# PCIe_SS1_TI_CONF register map
Vendor: Texas Instruments
Peripheral module from a debugger description file (folder am571x).
Registers are 32-bit, access per field, reset 0x0 unless marked. A register's access mark holds for its fields unless they carry their own. Offsets are as the file gives them; lines under a group give offsets from that group; [hi:lo] are bit positions; {n}, {i} and the like mark numbered series; 'fields as' and 'values as' point back to an identical list; <NAME> marks a mode.

## PCIe_SS1_TI_CONF
0x00 PCIECTRL_TI_CONF_REVISION ro reset not defined — IP Revision Identifier
  [31:0] REVISION — IP Revision
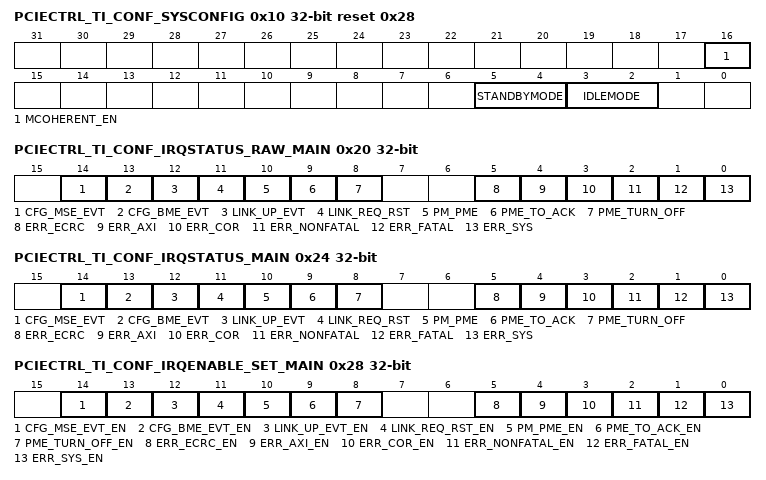
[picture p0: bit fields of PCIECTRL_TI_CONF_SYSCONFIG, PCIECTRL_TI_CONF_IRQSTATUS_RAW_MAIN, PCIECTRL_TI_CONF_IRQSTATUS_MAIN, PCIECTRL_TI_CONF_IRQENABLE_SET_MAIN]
0x10 PCIECTRL_TI_CONF_SYSCONFIG reset 0x28 — Controls various parameters of the master and slave interfaces.
  [16] MCOHERENT_EN rw — Allows the no-snoop (NS) attribute of inbound PCIe TLPs to be passed to SoC system bus (AXI) master as a 'coherent' inband flag.
    0=DIS (DIS AXI not coherent); 1=EN (EN AXI coherent = not(PCIE 'NS') that is, cache-coherence is preserved)
  [5:4] STANDBYMODE rw — PM mode of local initiator (master); Initiator may generate read/write transaction as long as it is out of STANDBY state. 0x0: Force-standby mode = Initiator is unconditionally placed in standby state. 0x1: No-standby mode = initiator is unconditionally placed out of standby state. 0x2: Smart-standby mode = initiator's standby state depends on internal conditions, that is, the module's functional requirements. Asynchronous wakeup events cannot be generated. 0x3: Smart-Standby, wakeup-capable mode = initiator's standby state depends on internal conditions, ie the module's functional requirements. Asynchronous wakeup events can be generated.
  [3:2] IDLEMODE rw — PM mode of local target (slave); Target shall be capable of handling read/write transaction as long as it is out of IDLE state. 0x0: Force-idle mode = local target's idle state follows (acknowledges) the system's idle requests unconditionally, regardless of the IP module's internal requirements. 0x1: No-idle mode = local target never enters idle state. 0x2: Smart-idle mode = local target's idle state eventually follows (acknowledges) the system's idle requests, depending on the IP module's internal requirements. Module shall not generate (IRQ- or DMA-request-related) wakeup events. 0x3: Smart-idle wakeup-capable mode: local target's idle state eventually follows (acknowledges) the system's idle requests, depending on the IP module's internal requirements. IP module may generate (IRQ- or DMA-request-related) wakeup events when in idle state.
0x18 PCIECTRL_TI_CONF_IRQ_EOI — Software End-Of-Interrupt: Allows the generation of further pulses on the interrupt line, if an new interrupt event is pending, when using the pulsed output. Unused when using the level interrupt line (depending on module integration).
  [3:0] LINE_NUMBER rw — Write the IRQ line number to apply software EOI to it. Write 0x0: software EOI on main interrupt line Read 0x0: Read always returns zeros Write 0x1: software EOI on message-signalled (MSI) interrupt line
0x20 PCIECTRL_TI_CONF_IRQSTATUS_RAW_MAIN access not given — Raw status of 'main' interrupt requests; Set even if event is not enabled. Write 1 to set the (raw) status, mostly for debug (regular status also gets set).
  [14] CFG_MSE_EVT — CFG 'Memory Space Enable' change IRQ status Write 0: No action Read 0: No event pending Write 1: Trigger IRQ event by software Read 1: IRQ event pending (access RW W1toSet)
  [13] CFG_BME_EVT — CFG 'Bus Master Enable' change IRQ status Write 0: No action Read 0: No event pending Write 1: Trigger IRQ event by software Read 1: IRQ event pending (access RW W1toSet)
  [12] LINK_UP_EVT — Link-up state change IRQ status Write 0: No action Read 0: No event pending Write 1: Trigger IRQ event by software Read 1: IRQ event pending (access RW W1toSet)
  [11] LINK_REQ_RST — Link Request Reset IRQ status Write 0: No action Read 0: No event pending Write 1: Trigger IRQ event by software Read 1: IRQ event pending (access RW W1toSet)
  [10] PM_PME — PM Power Management Event message received IRQ status Write 0: No action Read 0: No event pending Write 1: Trigger IRQ event by software Read 1: IRQ event pending (access RW W1toSet)
  [9] PME_TO_ACK — Power Management Event Turn-Off Ack message received IRQ status Write 0: No action Read 0: No event pending Write 1: Trigger IRQ event by software Read 1: IRQ event pending (access RW W1toSet)
  [8] PME_TURN_OFF — Power Management Event Turn-Off message received IRQ status Write 0: No action Read 0: No event pending Write 1: Trigger IRQ event by software Read 1: IRQ event pending (access RW W1toSet)
  [5] ERR_ECRC — ECRC Error IRQ status Write 0: No action Read 0: No event pending Write 1: Trigger IRQ event by software Read 1: IRQ event pending (access RW W1toSet)
  [4] ERR_AXI — AXI tag lookup fatal Error IRQ status Write 0: No action Read 0: No event pending Write 1: Trigger IRQ event by software Read 1: IRQ event pending (access RW W1toSet)
  [3] ERR_COR — Correctable Error message received IRQ status Write 0: No action Read 0: No event pending Write 1: Trigger IRQ event by software Read 1: IRQ event pending (access RW W1toSet)
  [2] ERR_NONFATAL — Non-Fatal Error message received IRQ status Write 0: No action Read 0: No event pending Write 1: Trigger IRQ event by software Read 1: IRQ event pending (access RW W1toSet)
  [1] ERR_FATAL — Fatal Error message received IRQ status Write 0: No action Read 0: No event pending Write 1: Trigger IRQ event by software Read 1: IRQ event pending (access RW W1toSet)
  [0] ERR_SYS — System Error IRQ status Write 0: No action Read 0: No event pending Write 1: Trigger IRQ event by software Read 1: IRQ event pending (access RW W1toSet)
0x24 PCIECTRL_TI_CONF_IRQSTATUS_MAIN access not given — Regular status of 'main' interrupt requests; Set only when enabled. Write 1 to clear after interrupt has been serviced (raw status also gets cleared).
  [14] CFG_MSE_EVT — CFG 'Memory Space Enable' change IRQ status Write 0: No action Read 0: No event pending Write 1: Clear pending event, if any Read 1: IRQ event pending (access RW W1toClr)
  [13] CFG_BME_EVT — CFG 'Bus Master Enable' change IRQ status Write 0: No action Read 0: No event pending Write 1: Clear pending event, if any Read 1: IRQ event pending (access RW W1toClr)
  [12] LINK_UP_EVT — Link-up state change IRQ status Write 0: No action Read 0: No event pending Write 1: Clear pending event, if any Read 1: IRQ event pending (access RW W1toClr)
  [11] LINK_REQ_RST — Link Request Reset IRQ status Write 0: No action Read 0: No event pending Write 1: Clear pending event, if any Read 1: IRQ event pending (access RW W1toClr)
  [10] PM_PME — PM Power Management Event message received IRQ status Write 0: No action Read 0: No event pending Write 1: Clear pending event, if any Read 1: IRQ event pending (access RW W1toClr)
  [9] PME_TO_ACK — Power Management Event Turn-Off Ack message received IRQ status Write 0: No action Read 0: No event pending Write 1: Clear pending event, if any Read 1: IRQ event pending (access RW W1toClr)
  [8] PME_TURN_OFF — Power Management Event Turn-Off message received IRQ status Write 0: No action Read 0: No event pending Write 1: Clear pending event, if any Read 1: IRQ event pending (access RW W1toClr)
  [5] ERR_ECRC — ECRC Error IRQ status Write 0: No action Read 0: No event pending Write 1: Clear pending event, if any Read 1: IRQ event pending (access RW W1toClr)
  [4] ERR_AXI — AXI tag lookup fatal Error IRQ status Write 0: No action Read 0: No event pending Write 1: Clear pending event, if any Read 1: IRQ event pending (access RW W1toClr)
  [3] ERR_COR — Correctable Error message received IRQ status Write 0: No action Read 0: No event pending Write 1: Clear pending event, if any Read 1: IRQ event pending (access RW W1toClr)
  [2] ERR_NONFATAL — Non-Fatal Error message received IRQ status Write 0: No action Read 0: No event pending Write 1: Clear pending event, if any Read 1: IRQ event pending (access RW W1toClr)
  [1] ERR_FATAL — Fatal Error message received IRQ status Write 0: No action Read 0: No event pending Write 1: Clear pending event, if any Read 1: IRQ event pending (access RW W1toClr)
  [0] ERR_SYS — System Error IRQ status Write 0: No action Read 0: No event pending Write 1: Clear pending event, if any Read 1: IRQ event pending (access RW W1toClr)
0x28 PCIECTRL_TI_CONF_IRQENABLE_SET_MAIN access not given — Enable of 'main' interrupt requests; Write 1 to set (ie to enable interrupt). Readout is the same as corresponding _CLR register.
  [14] CFG_MSE_EVT_EN — CFG 'Memory Space Enable' change IRQ enable Write 0: No action Read 0: IRQ event is disabled Write 1: Set IRQ enable (that is, enable event) Read 1: IRQ event is enabled (access RW W1toSet)
  [13] CFG_BME_EVT_EN — CFG 'Bus Master Enable' change IRQ enable Write 0: No action Read 0: IRQ event is disabled Write 1: Set IRQ enable (that is, enable event) Read 1: IRQ event is enabled (access RW W1toSet)
  [12] LINK_UP_EVT_EN — Link-up state change IRQ enable Write 0: No action Read 0: IRQ event is disabled Write 1: Set IRQ enable (that is, enable event) Read 1: IRQ event is enabled (access RW W1toSet)
  [11] LINK_REQ_RST_EN — Link Request Reset IRQ enable Write 0: No action Read 0: IRQ event is disabled Write 1: Set IRQ enable (that is, enable event) Read 1: IRQ event is enabled (access RW W1toSet)
  [10] PM_PME_EN — PM Power Management Event message received IRQ enable Write 0: No action Read 0: IRQ event is disabled Write 1: Set IRQ enable (that is, enable event) Read 1: IRQ event is enabled (access RW W1toSet)
  [9] PME_TO_ACK_EN — Power Management Event Turn-Off Ack message received IRQ enable Write 0: No action Read 0: IRQ event is disabled Write 1: Set IRQ enable (that is, enable event) Read 1: IRQ event is enabled (access RW W1toSet)
  [8] PME_TURN_OFF_EN — Power Management Event Turn-Off message received IRQ enable Write 0: No action Read 0: IRQ event is disabled Write 1: Set IRQ enable (that is, enable event) Read 1: IRQ event is enabled (access RW W1toSet)
  [5] ERR_ECRC_EN — ECRC Error IRQ enable Write 0: No action Read 0: IRQ event is disabled Write 1: Set IRQ enable (that is, enable event) Read 1: IRQ event is enabled (access RW W1toSet)
  [4] ERR_AXI_EN — AXI tag lookup fatal Error IRQ enable Write 0: No action Read 0: IRQ event is disabled Write 1: Set IRQ enable (that is, enable event) Read 1: IRQ event is enabled (access RW W1toSet)
  [3] ERR_COR_EN — Correctable Error message received IRQ enable Write 0: No action Read 0: IRQ event is disabled Write 1: Set IRQ enable (that is, enable event) Read 1: IRQ event is enabled (access RW W1toSet)
  [2] ERR_NONFATAL_EN — Non-Fatal Error message received IRQ enable Write 0: No action Read 0: IRQ event is disabled Write 1: Set IRQ enable (that is, enable event) Read 1: IRQ event is enabled (access RW W1toSet)
  [1] ERR_FATAL_EN — Fatal Error message received IRQ enable Write 0: No action Read 0: IRQ event is disabled Write 1: Set IRQ enable (that is, enable event) Read 1: IRQ event is enabled (access RW W1toSet)
  [0] ERR_SYS_EN — System Error IRQ enable Write 0: No action Read 0: IRQ event is disabled Write 1: Set IRQ enable (that is, enable event) Read 1: IRQ event is enabled (access RW W1toSet)
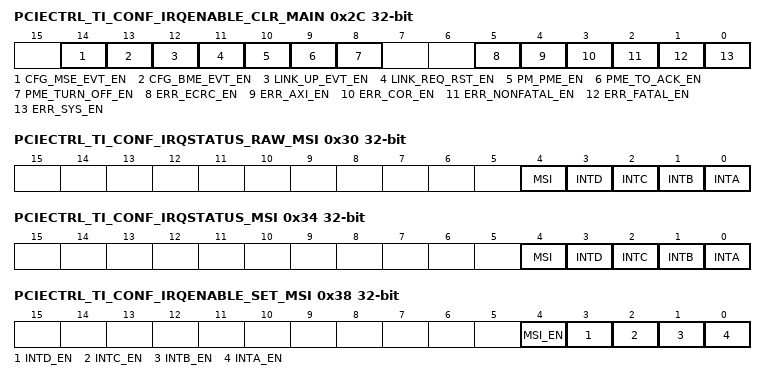
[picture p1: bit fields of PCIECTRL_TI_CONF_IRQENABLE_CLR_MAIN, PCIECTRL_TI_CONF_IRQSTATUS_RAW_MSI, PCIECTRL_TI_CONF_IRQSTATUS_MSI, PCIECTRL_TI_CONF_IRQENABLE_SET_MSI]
0x2C PCIECTRL_TI_CONF_IRQENABLE_CLR_MAIN access not given — Enable of 'main' interrupt requests; Write 1 to clear (ie to disable interrupt). Readout is the same as corresponding _SET register.
  [14] CFG_MSE_EVT_EN — CFG 'Memory Space Enable' change IRQ enable Write 0: No action Read 0: IRQ event is disabled Write 1: Clear IRQ enable (that is, disable event) Read 1: IRQ event is enabled (access RW Wr1toClr)
  [13] CFG_BME_EVT_EN — CFG 'Bus Master Enable' change IRQ enable Write 0: No action Read 0: IRQ event is disabled Write 1: Clear IRQ enable (that is, disable event) Read 1: IRQ event is enabled (access RW Wr1toClr)
  [12] LINK_UP_EVT_EN — Link-up state change IRQ enable Write 0: No action Read 0: IRQ event is disabled Write 1: Clear IRQ enable (that is, disable event) Read 1: IRQ event is enabled (access RW Wr1toClr)
  [11] LINK_REQ_RST_EN — Link Request Reset IRQ enable Write 0: No action Read 0: IRQ event is disabled Write 1: Clear IRQ enable (that is, disable event) Read 1: IRQ event is enabled (access RW Wr1toClr)
  [10] PM_PME_EN — PM Power Management Event message received IRQ enable Write 0: No action Read 0: IRQ event is disabled Write 1: Clear IRQ enable (that is, disable event) Read 1: IRQ event is enabled (access RW Wr1toClr)
  [9] PME_TO_ACK_EN — Power Management Event Turn-Off Ack message received IRQ enable Write 0: No action Read 0: IRQ event is disabled Write 1: Clear IRQ enable (that is, disable event) Read 1: IRQ event is enabled (access RW Wr1toClr)
  [8] PME_TURN_OFF_EN — Power Management Event Turn-Off message received IRQ enable Write 0: No action Read 0: IRQ event is disabled Write 1: Clear IRQ enable (that is, disable event) Read 1: IRQ event is enabled (access RW Wr1toClr)
  [5] ERR_ECRC_EN — ECRC Error IRQ enable Write 0: No action Read 0: IRQ event is disabled Write 1: Clear IRQ enable (that is, disable event) Read 1: IRQ event is enabled (access RW Wr1toClr)
  [4] ERR_AXI_EN — AXI tag lookup fatal Error IRQ enable Write 0: No action Read 0: IRQ event is disabled Write 1: Clear IRQ enable (that is, disable event) Read 1: IRQ event is enabled (access RW Wr1toClr)
  [3] ERR_COR_EN — Correctable Error message received IRQ enable Write 0: No action Read 0: IRQ event is disabled Write 1: Clear IRQ enable (that is, disable event) Read 1: IRQ event is enabled (access RW Wr1toClr)
  [2] ERR_NONFATAL_EN — Non-Fatal Error message received IRQ enable Write 0: No action Read 0: IRQ event is disabled Write 1: Clear IRQ enable (that is, disable event) Read 1: IRQ event is enabled (access RW Wr1toClr)
  [1] ERR_FATAL_EN — Fatal Error message received IRQ enable Write 0: No action Read 0: IRQ event is disabled Write 1: Clear IRQ enable (that is, disable event) Read 1: IRQ event is enabled (access RW Wr1toClr)
  [0] ERR_SYS_EN — System Error IRQ enable Write 0: No action Read 0: IRQ event is disabled Write 1: Clear IRQ enable (that is, disable event) Read 1: IRQ event is enabled (access RW Wr1toClr)
0x30 PCIECTRL_TI_CONF_IRQSTATUS_RAW_MSI access not given — Raw status of legacy and MSI interrupt requests; Set even if event is not enabled. Write 1 to set the (raw) status, mostly for debug (regular status also gets set).
  [4] MSI — Message Signaled Interrupt IRQ status Write 0: No action Read 0: No event pending Write 1: Trigger IRQ event by software Read 1: IRQ event pending (access RW W1toSet)
  [3] INTD — INTD IRQ status (Legacy PCIe message interrupt D); RC mode only. Write 0: No action Read 0: No event pending Write 1: Trigger IRQ event by software Read 1: IRQ event pending (access RW W1toSet)
  [2] INTC — INTC IRQ status (Legacy PCIe message interrupt C); RC mode only. Write 0: No action Read 0: No event pending Write 1: Trigger IRQ event by software Read 1: IRQ event pending (access RW W1toSet)
  [1] INTB — INTB IRQ status (Legacy PCIe message interrupt B); RC mode only. Write 0: No action Read 0: No event pending Write 1: Trigger IRQ event by software Read 1: IRQ event pending (access RW W1toSet)
  [0] INTA — INTA IRQ status (Legacy PCIe message interrupt A); RC mode only. Write 0: No action Read 0: No event pending Write 1: Trigger IRQ event by software Read 1: IRQ event pending (access RW W1toSet)
0x34 PCIECTRL_TI_CONF_IRQSTATUS_MSI access not given — Regular status of legacy and MSI interrupt requests; Set only when enabled. Write 1 to clear after interrupt has been serviced (raw status also gets cleared). HW-generated events are self-clearing.
  [4] MSI — Message Signaled Interrupt IRQ status. Cleared by clearing all vectors in the MSI controller (PL) registers Write 0: No action Read 0: No event pending Write 1: Clear pending event, if any. Read 1: IRQ event pending (access RW W1toClr)
  [3] INTD — INTD IRQ status (Legacy PCIe message interrupt D); RC mode only. Typically set AND cleared by the remote EP, without local software intervention. Write 0: No action Read 0: No event pending Write 1: Clear pending event, if any. Read 1: IRQ event pending (access RW W1toClr)
  [2] INTC — INTC IRQ status (Legacy PCIe message interrupt C); RC mode only. Typically set AND cleared by the remote EP, without local software intervention. Write 0: No action Read 0: No event pending Write 1: Clear pending event, if any. Read 1: IRQ event pending (access RW W1toClr)
  [1] INTB — INTB IRQ status (Legacy PCIe message interrupt B); RC mode only. Typically set AND cleared by the remote EP, without local software intervention. Write 0: No action Read 0: No event pending Write 1: Clear pending event, if any. Read 1: IRQ event pending (access RW W1toClr)
  [0] INTA — INTA IRQ status (Legacy PCIe message interrupt A); RC mode only. Typically set AND cleared by the remote EP, without local software intervention. Write 0: No action Read 0: No event pending Write 1: Clear pending event, if any. Read 1: IRQ event pending (access RW W1toClr)
0x38 PCIECTRL_TI_CONF_IRQENABLE_SET_MSI access not given — Enable of legacy and MSI interrupt requests; Write 1 to set (ie to enable interrupt). Readout is the same as corresponding _CLR register.
  [4] MSI_EN — Message Signaled Interrupt IRQ enable Write 0: No action Read 0: IRQ event is disabled Write 1: Set IRQ enable (that is, enable event) Read 1: IRQ event is enabled (access RW W1toSet)
  [3] INTD_EN — INTD IRQ enable Write 0: No action Read 0: IRQ event is disabled Write 1: Set IRQ enable (that is, enable event) Read 1: IRQ event is enabled (access RW W1toSet)
  [2] INTC_EN — INTC IRQ enable Write 0: No action Read 0: IRQ event is disabled Write 1: Set IRQ enable (that is, enable event) Read 1: IRQ event is enabled (access RW W1toSet)
  [1] INTB_EN — INTB IRQ enable Write 0: No action Read 0: IRQ event is disabled Write 1: Set IRQ enable (that is, enable event) Read 1: IRQ event is enabled (access RW W1toSet)
  [0] INTA_EN — INTA IRQ enable Write 0: No action Read 0: IRQ event is disabled Write 1: Set IRQ enable (that is, enable event) Read 1: IRQ event is enabled (access RW W1toSet)
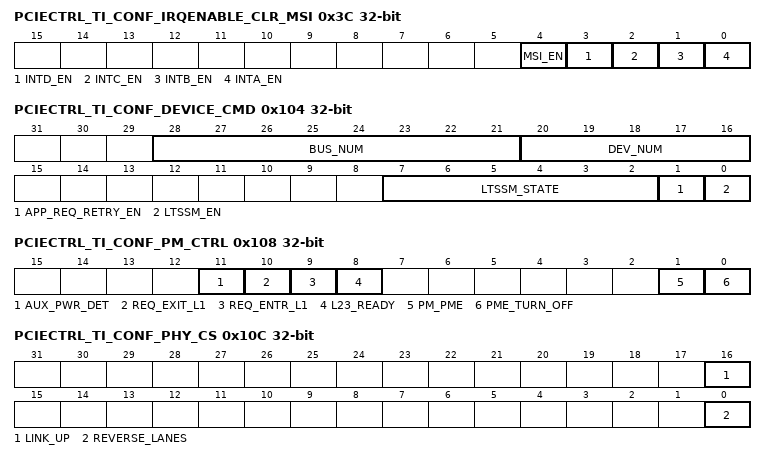
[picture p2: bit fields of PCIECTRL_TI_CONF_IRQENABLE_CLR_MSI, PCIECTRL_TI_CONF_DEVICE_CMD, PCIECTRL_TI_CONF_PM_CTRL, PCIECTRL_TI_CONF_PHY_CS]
0x3C PCIECTRL_TI_CONF_IRQENABLE_CLR_MSI access not given — Enable of legacy and MSI interrupt requests; Write 1 to clear (ie to disable interrupt). Readout is the same as corresponding _SET register.
  [4] MSI_EN — Message Signaled Interrupt IRQ enable Write 0: No action Read 0: IRQ event is disabled Write 1: Clear IRQ enable (that is, disable event) Read 1: IRQ event is enabled (access RW W1toClr)
  [3] INTD_EN — INTD IRQ enable Write 0: No action Read 0: IRQ event is disabled Write 1: Clear IRQ enable (that is, disable event) Read 1: IRQ event is enabled (access RW W1toClr)
  [2] INTC_EN — INTC IRQ enable Write 0: No action Read 0: IRQ event is disabled Write 1: Clear IRQ enable (that is, disable event) Read 1: IRQ event is enabled (access RW W1toClr)
  [1] INTB_EN — INTB IRQ enable Write 0: No action Read 0: IRQ event is disabled Write 1: Clear IRQ enable (that is, disable event) Read 1: IRQ event is enabled (access RW W1toClr)
  [0] INTA_EN — INTA IRQ enable Write 0: No action Read 0: IRQ event is disabled Write 1: Clear IRQ enable (that is, disable event) Read 1: IRQ event is enabled (access RW W1toClr)
0x100 PCIECTRL_TI_CONF_DEVICE_TYPE reset 0x4 — Sets the Dual-Mode device's type
  [3:0] TYPE rw — PCIe device type including the contents of the PCI config space (Type-0 for EP, Type-1 for RC); Apply fundamental reset after change; Do not change during core operation; 0x0: PCIe endpoint (EP) 0x1: Legacy PCIe endpoint (LEG_EP) 0x4: Root Complex (RC) Other values: Reserved
0x104 PCIECTRL_TI_CONF_DEVICE_CMD — Device command (startup control and status); WARNING: cleared by all reset conditions, including fundamental reset
  [28:21] BUS_NUM ro — PCIe bus number
  [20:16] DEV_NUM ro — PCIe device number
  [7:2] LTSSM_STATE ro — LTSSM state /substate, implementation-specific, for debug Read 0x00: DETECT_QUIET Read 0x01: DETECT_ACT Read 0x02: POLL_ACTIVE Read 0x03: POLL_COMPLIANCE Read 0x04: POLL_CONFIG Read 0x05: PRE_DETECT_QUIET Read 0x06: DETECT_WAIT Read 0x07: CFG_LINKWD_START Read 0x08: CFG_LINKWD_ACEPT Read 0x09: CFG_LANENUM_WAIT Read 0x0A: CFG_LANENUM_ACEPT Read 0x0B: CFG_COMPLETE Read 0x0C: CFG_IDLE Read 0x0D: RCVRY_LOCK Read 0x0E: RCVRY_SPEED Read 0x0F: RCVRY_RCVRCFG Read 0x10: RCVRY_IDLE Read 0x11: L0 Read 0x12: L0S Read 0x13: L123_SEND_EIDLE Read 0x14: L1_IDLE Read 0x15: L2_IDLE Read 0x16: L2_WAKE Read 0x17: DISABLED_ENTRY Read 0x18: DISABLED_IDLE Read 0x19: DISABLED Read 0x1A: LPBK_ENTRY Read 0x1B: LPBK_ACTIVE Read 0x1C: LPBK_EXIT Read 0x1D: LPBK_EXIT_TIMEOUT Read 0x1E: HOT_RESET_ENTRY Read 0x1F: HOT_RESET Read 0x20: RCVRY_EQ0 Read 0x21: RCVRY_EQ1 Read 0x22: RCVRY_EQ2 Read 0x23: RCVRY_EQ3
  [1] APP_REQ_RETRY_EN rw — Application Request Retry Enable (This bit is CLEARED BY FUNDAMENTAL RESET)
    0=DISABLED (DISABLED Incoming PCI transactions are processed normally); 1=ENABLED (ENABLED Incoming PCI transactions are responded with 'retry')
  [0] LTSSM_EN rw — LTSSM enable: start the PCI link (This bit is CLEARED BY FUNDAMENTAL RESET)
    0=DISABLED; 1=ENABLED
0x108 PCIECTRL_TI_CONF_PM_CTRL — Power Management Control
  [11] AUX_PWR_DET rw — Auxilliary Power Detection; Status of Vaux detection for the PCIe controller; Determines transition to L2 vs L3 upon Vmain turn-off.
    0=UNPOWERED (UNPOWERED Vaux not present: D3cold maps to L3 link state); 1=POWERED (POWERED Vaux present: D3cold maps to L2 link state)
  [10] REQ_EXIT_L1 rw — Request to exit L1 state (to L0)
    0=INACTIVE (INACTIVE No request); 1=ACTIVE (ACTIVE L1 exit request)
  [9] REQ_ENTR_L1 rw — Request to transition to L1 state
    0=INACTIVE (INACTIVE No request); 1=ACTIVE (ACTIVE L1 entry request)
  [8] L23_READY rw — Indicates system readiness for the link to enter L2/L3 ready state (EP mode only); Allows the transmission of PM_Enter_L23 following PM_Turn_OFF/PME_TO_Ack handshake. Self-cleared upon transition to L2/L3.
    0=NOT_READY; 1=READY
  [1] PM_PME wo — Transmits PM_PME wakeup message (EP mode only)
    0=NOACTION; 1=TRANSMIT
  [0] PME_TURN_OFF wo — Transmits PME_Turn_Off message downstream (RC mode only); Eventually sends all links of hierarchy domain to L2L/3_ready
    0=NOACTION; 1=TRANSMIT
0x10C PCIECTRL_TI_CONF_PHY_CS — Physical Layer Control and Status
  [16] LINK_UP ro — Link status, from LTSSM
    0=DOWN; 1=UP
  [0] REVERSE_LANES rw — Manual lane reversal control, allowing lane 0 and lane 1 to be swapped by default; Both Tx and Rx are reversed; Polarity of the individual lane is unchanged
    0=STRAIGHT; 1=REVERSED
0x124 PCIECTRL_TI_CONF_INTX_ASSERT — Legacy INTx ASSERT message control, with 'x' in (A,B,C,D) set by the 'Interrupt Pin' field. Write 1 to send message, read to get the status; EP mode only
  [0] ASSERT_F0 rw — INTx ASSERT for function 0 Write 0: No action Read 0: INTx is inactive (has been deasserted) Write 1: Transmit INTx ASSERT to RC Read 1: INTx is active (has been asserted)
0x128 PCIECTRL_TI_CONF_INTX_DEASSERT — Legacy INTx DEASSERT message control, with 'x' in (A,B,C,D) set by the 'Interrupt Pin' field. Write 1 to send message, read to get the status; EP mode only
  [0] DEASSERT_F0 rw — INTx DEASSERT for function 0 Write 0: No action Read 0: INTx is inactive (has been deasserted) Write 1: Transmit INTx DEASSERT to RC Read 1: INTx is active (has been asserted)
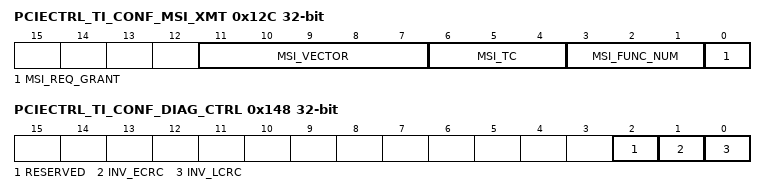
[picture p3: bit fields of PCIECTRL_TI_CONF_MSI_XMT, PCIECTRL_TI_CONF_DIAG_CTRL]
0x12C PCIECTRL_TI_CONF_MSI_XMT — MSI transmitter (EP mode); Specifies parameters of MSI, together with MSI capability descriptor already configured by remote RC.
  [11:7] MSI_VECTOR rw — Vector number for transmitted MSI (as allowed by RC at enumeration)
  [6:4] MSI_TC rw — Traffic class (TC) for transmitted MSI
  [3:1] MSI_FUNC_NUM rw — Function number for transmitted MSI; Always 0 for single-function EP
  [0] MSI_REQ_GRANT rw — MSI transmit request (and grant status) Write 0: No Action Read 0: MSI transmission request pending Read 1: No MSI request pending (last request granted) Write 1: Request MSI transmission
0x140 PCIECTRL_TI_CONF_DEBUG_CFG — Configuration of debug_data output and register (observability)
  [5:0] SEL rw — Debug_data mode
0x144 PCIECTRL_TI_CONF_DEBUG_DATA ro — Debug data vector, depending on DEBUG_CFG.sel value
  [31:0] DEBUG
0x148 PCIECTRL_TI_CONF_DIAG_CTRL — Diagnostic control
  [2] RESERVED rw — software must always keep this bit at its default value - 0.
  [1] INV_ECRC rw — Corrupt LSB of ECRC in the next packet, then self-clears. Read 0: No CRC corruption pending Read 1: CRC corruption pending Write 1: Request CRC corruption
  [0] INV_LCRC rw — Corrupts LSB of LCRC in the next packet, then self-clears. Read 0: No CRC corruption pending Read 1: CRC corruption pending Write 1: Request CRC corruption
